VERSION ""

NS_ :

BS_:

BU_:

BO_ 3221225472 VECTOR__INDEPENDENT_SIG_MSG: 0 Vector__XXX
 SG_ New_Signal_1_Copy_8 : 0|8@0+ (1,0) [-128|127] "" Vector__XXX

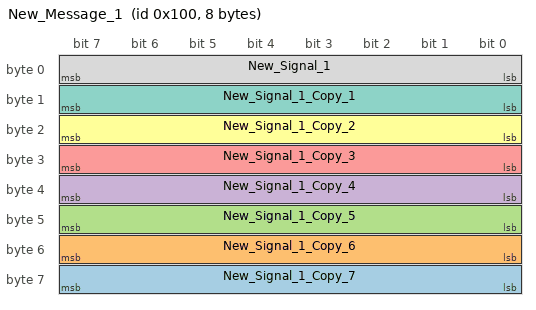
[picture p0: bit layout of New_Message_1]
BO_ 256 New_Message_1: 8 Vector__XXX
 SG_ New_Signal_1_Copy_7 : 63|8@0+ (1,0) [-128|127] "" Vector__XXX
 SG_ New_Signal_1_Copy_6 : 55|8@0+ (1,0) [-128|127] "" Vector__XXX
 SG_ New_Signal_1_Copy_5 : 47|8@0+ (1,0) [-128|127] "" Vector__XXX
 SG_ New_Signal_1_Copy_4 : 39|8@0+ (1,0) [-128|127] "" Vector__XXX
 SG_ New_Signal_1_Copy_3 : 31|8@0+ (1,0) [-128|127] "" Vector__XXX
 SG_ New_Signal_1_Copy_2 : 23|8@0+ (1,0) [-128|127] "" Vector__XXX
 SG_ New_Signal_1_Copy_1 : 15|8@0+ (1,0) [-128|127] "" Vector__XXX
 SG_ New_Signal_1 : 7|8@0+ (1,0) [-128|127] "" Vector__XXX

CM_ BO_ 3221225472 "This is a message for not used signals, created by Vector CANdb++ DBC OLE DB Provider.";
BA_DEF_ BO_  "CANFD_BRS" ENUM  "0","1";
BA_DEF_  "DBName" STRING ;
BA_DEF_  "BusType" STRING ;
BA_DEF_ BO_  "VFrameFormat" ENUM  "StandardCAN","ExtendedCAN","reserved","reserved","reserved","reserved","reserved","reserved","reserved","reserved","reserved","reserved","reserved","reserved","StandardCAN_FD","ExtendedCAN_FD";
BA_DEF_DEF_  "CANFD_BRS" "1";
BA_DEF_DEF_  "DBName" "";
BA_DEF_DEF_  "BusType" "";
BA_DEF_DEF_  "VFrameFormat" "StandardCAN";
BA_ "BusType" "CAN FD";
BA_ "DBName" "aaaaa";
